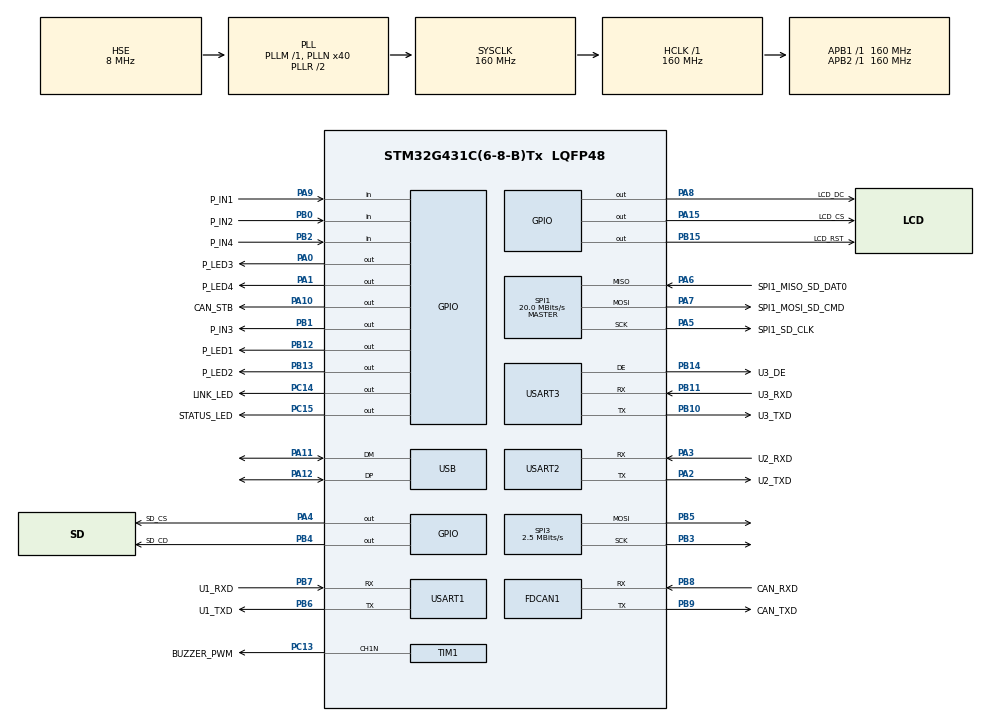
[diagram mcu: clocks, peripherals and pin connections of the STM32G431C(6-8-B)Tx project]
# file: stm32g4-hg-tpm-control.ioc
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Dma.Request0=USART2_RX
Dma.Request1=USART1_RX
Dma.Request2=USART3_RX
Dma.Request3=SPI1_RX
Dma.Request4=SPI1_TX
Dma.SPI1_RX.3.Direction=DMA_PERIPH_TO_MEMORY
Dma.SPI1_RX.3.EventEnable=DISABLE
Dma.SPI1_RX.3.Instance=DMA1_Channel3
Dma.SPI1_RX.3.MemDataAlignment=DMA_MDATAALIGN_BYTE
Dma.SPI1_RX.3.MemInc=DMA_MINC_ENABLE
Dma.SPI1_RX.3.Mode=DMA_CIRCULAR
Dma.SPI1_RX.3.PeriphDataAlignment=DMA_PDATAALIGN_BYTE
Dma.SPI1_RX.3.PeriphInc=DMA_PINC_DISABLE
Dma.SPI1_RX.3.Polarity=HAL_DMAMUX_REQ_GEN_RISING
Dma.SPI1_RX.3.Priority=DMA_PRIORITY_LOW
Dma.SPI1_RX.3.RequestNumber=1
Dma.SPI1_RX.3.SignalID=NONE
Dma.SPI1_RX.3.SyncEnable=DISABLE
Dma.SPI1_RX.3.SyncPolarity=HAL_DMAMUX_SYNC_NO_EVENT
Dma.SPI1_RX.3.SyncRequestNumber=1
Dma.SPI1_RX.3.SyncSignalID=NONE
Dma.SPI1_TX.4.Direction=DMA_MEMORY_TO_PERIPH
Dma.SPI1_TX.4.EventEnable=DISABLE
Dma.SPI1_TX.4.Instance=DMA1_Channel4
Dma.SPI1_TX.4.MemDataAlignment=DMA_MDATAALIGN_BYTE
Dma.SPI1_TX.4.MemInc=DMA_MINC_ENABLE
Dma.SPI1_TX.4.Mode=DMA_CIRCULAR
Dma.SPI1_TX.4.PeriphDataAlignment=DMA_PDATAALIGN_BYTE
Dma.SPI1_TX.4.PeriphInc=DMA_PINC_DISABLE
Dma.SPI1_TX.4.Polarity=HAL_DMAMUX_REQ_GEN_RISING
Dma.SPI1_TX.4.Priority=DMA_PRIORITY_LOW
Dma.SPI1_TX.4.RequestNumber=1
Dma.SPI1_TX.4.SignalID=NONE
Dma.SPI1_TX.4.SyncEnable=DISABLE
Dma.SPI1_TX.4.SyncPolarity=HAL_DMAMUX_SYNC_NO_EVENT
Dma.SPI1_TX.4.SyncRequestNumber=1
Dma.SPI1_TX.4.SyncSignalID=NONE
Dma.USART1_RX.1.Direction=DMA_PERIPH_TO_MEMORY
Dma.USART1_RX.1.EventEnable=DISABLE
Dma.USART1_RX.1.Instance=DMA1_Channel5
Dma.USART1_RX.1.MemDataAlignment=DMA_MDATAALIGN_BYTE
Dma.USART1_RX.1.MemInc=DMA_MINC_ENABLE
Dma.USART1_RX.1.Mode=DMA_CIRCULAR
Dma.USART1_RX.1.PeriphDataAlignment=DMA_PDATAALIGN_BYTE
Dma.USART1_RX.1.PeriphInc=DMA_PINC_DISABLE
Dma.USART1_RX.1.Polarity=HAL_DMAMUX_REQ_GEN_RISING
Dma.USART1_RX.1.Priority=DMA_PRIORITY_LOW
Dma.USART1_RX.1.RequestNumber=1
Dma.USART1_RX.1.SignalID=NONE
Dma.USART1_RX.1.SyncEnable=DISABLE
Dma.USART1_RX.1.SyncPolarity=HAL_DMAMUX_SYNC_NO_EVENT
Dma.USART1_RX.1.SyncRequestNumber=1
Dma.USART1_RX.1.SyncSignalID=NONE
Dma.USART2_RX.0.Direction=DMA_PERIPH_TO_MEMORY
Dma.USART2_RX.0.EventEnable=DISABLE
Dma.USART2_RX.0.Instance=DMA1_Channel1
Dma.USART2_RX.0.MemDataAlignment=DMA_MDATAALIGN_BYTE
Dma.USART2_RX.0.MemInc=DMA_MINC_ENABLE
Dma.USART2_RX.0.Mode=DMA_CIRCULAR
Dma.USART2_RX.0.PeriphDataAlignment=DMA_PDATAALIGN_BYTE
Dma.USART2_RX.0.PeriphInc=DMA_PINC_DISABLE
Dma.USART2_RX.0.Polarity=HAL_DMAMUX_REQ_GEN_RISING
Dma.USART2_RX.0.Priority=DMA_PRIORITY_LOW
Dma.USART2_RX.0.RequestNumber=1
Dma.USART2_RX.0.SignalID=NONE
Dma.USART2_RX.0.SyncEnable=DISABLE
Dma.USART2_RX.0.SyncPolarity=HAL_DMAMUX_SYNC_NO_EVENT
Dma.USART2_RX.0.SyncRequestNumber=1
Dma.USART2_RX.0.SyncSignalID=NONE
Dma.USART3_RX.2.Direction=DMA_PERIPH_TO_MEMORY
Dma.USART3_RX.2.EventEnable=DISABLE
Dma.USART3_RX.2.Instance=DMA1_Channel2
Dma.USART3_RX.2.MemDataAlignment=DMA_MDATAALIGN_BYTE
Dma.USART3_RX.2.MemInc=DMA_MINC_ENABLE
Dma.USART3_RX.2.Mode=DMA_CIRCULAR
Dma.USART3_RX.2.PeriphDataAlignment=DMA_PDATAALIGN_BYTE
Dma.USART3_RX.2.PeriphInc=DMA_PINC_DISABLE
Dma.USART3_RX.2.Polarity=HAL_DMAMUX_REQ_GEN_RISING
Dma.USART3_RX.2.Priority=DMA_PRIORITY_LOW
Dma.USART3_RX.2.RequestNumber=1
Dma.USART3_RX.2.SignalID=NONE
Dma.USART3_RX.2.SyncEnable=DISABLE
Dma.USART3_RX.2.SyncPolarity=HAL_DMAMUX_SYNC_NO_EVENT
Dma.USART3_RX.2.SyncRequestNumber=1
Dma.USART3_RX.2.SyncSignalID=NONE
FDCAN1.CalculateBaudRateNominal=1000000
FDCAN1.CalculateTimeBitNominal=1000
FDCAN1.CalculateTimeQuantumNominal=200.0
FDCAN1.ExtFiltersNbr=8
FDCAN1.StdFiltersNbr=28
Mcu.Family=STM32G4
Mcu.Name=STM32G431C(6-8-B)Tx
Mcu.Package=LQFP48
NVIC.FDCAN1_IT0_IRQn=true\:0\:0\:false\:false\:true\:true\:true\:true
NVIC.PriorityGroup=NVIC_PRIORITYGROUP_4
NVIC.USB_LP_IRQn=true\:0\:0\:false\:false\:true\:false\:true\:true
PA0.GPIO_Label=P_LED3
PA0.Signal=GPIO_Output
PA1.GPIO_Label=P_LED4
PA1.Signal=GPIO_Output
PA10.GPIO_Label=CAN_STB
PA10.PinState=GPIO_PIN_RESET
PA10.Signal=GPIO_Output
PA11.Mode=Device
PA11.Signal=USB_DM
PA12.Mode=Device
PA12.Signal=USB_DP
PA13.Mode=Serial_Wire
PA13.Signal=SYS_JTMS-SWDIO
PA14.Mode=Serial_Wire
PA14.Signal=SYS_JTCK-SWCLK
PA15.GPIO_Label=LCD_CS
PA15.Signal=GPIO_Output
PA2.GPIO_Label=U2_TXD
PA2.Mode=Asynchronous
PA2.Signal=USART2_TX
PA3.GPIO_Label=U2_RXD
PA3.Mode=Asynchronous
PA3.Signal=USART2_RX
PA4.GPIO_Label=SD_CS
PA4.Signal=GPIO_Output
PA5.GPIO_Label=SPI1_SD_CLK
PA5.GPIO_Speed=GPIO_SPEED_FREQ_VERY_HIGH
PA5.Mode=Full_Duplex_Master
PA5.Signal=SPI1_SCK
PA6.GPIO_Label=SPI1_MISO_SD_DAT0
PA6.GPIO_Speed=GPIO_SPEED_FREQ_VERY_HIGH
PA6.Mode=Full_Duplex_Master
PA6.Signal=SPI1_MISO
PA7.GPIO_Label=SPI1_MOSI_SD_CMD
PA7.GPIO_Speed=GPIO_SPEED_FREQ_VERY_HIGH
PA7.Mode=Full_Duplex_Master
PA7.Signal=SPI1_MOSI
PA8.GPIO_Label=LCD_DC
PA8.Signal=GPIO_Output
PA9.GPIO_Label=P_IN1
PA9.Signal=GPIO_Input
PB0.GPIO_Label=P_IN2
PB0.Signal=GPIO_Input
PB1.GPIO_Label=P_IN3
PB1.Signal=GPIO_Output
PB10.GPIO_Label=U3_TXD
PB10.Mode=Asynchronous
PB10.Signal=USART3_TX
PB11.GPIO_Label=U3_RXD
PB11.Mode=Asynchronous
PB11.Signal=USART3_RX
PB12.GPIO_Label=P_LED1
PB12.Signal=GPIO_Output
PB13.GPIO_Label=P_LED2
PB13.Signal=GPIO_Output
PB14.GPIO_Label=U3_DE
PB14.Mode=Hardware Flow Control (RS485)
PB14.Signal=USART3_DE
PB15.GPIO_Label=LCD_RST
PB15.Signal=GPIO_Output
PB2.GPIO_Label=P_IN4
PB2.Signal=GPIO_Input
PB3.GPIO_Speed=GPIO_SPEED_FREQ_VERY_HIGH
PB3.Mode=TX_Only_Simplex_Unidirect_Master
PB3.Signal=SPI3_SCK
PB4.GPIO_Label=SD_CD
PB4.Signal=GPIO_Output
PB5.GPIO_Speed=GPIO_SPEED_FREQ_VERY_HIGH
PB5.Mode=TX_Only_Simplex_Unidirect_Master
PB5.Signal=SPI3_MOSI
PB6.GPIO_Label=U1_TXD
PB6.Mode=Asynchronous
PB6.Signal=USART1_TX
PB7.GPIO_Label=U1_RXD
PB7.Mode=Asynchronous
PB7.Signal=USART1_RX
PB8-BOOT0.GPIO_Label=CAN_RXD
PB8-BOOT0.Mode=FDCAN_Activate
PB8-BOOT0.Signal=FDCAN1_RX
PB9.GPIO_Label=CAN_TXD
PB9.Mode=FDCAN_Activate
PB9.Signal=FDCAN1_TX
PC13.GPIO_Label=BUZZER_PWM
PC13.Mode=PWM Generation1 CH1N
PC13.Signal=TIM1_CH1N
PC14-OSC32_IN.GPIO_Label=LINK_LED
PC14-OSC32_IN.Signal=GPIO_Output
PC15-OSC32_OUT.GPIO_Label=STATUS_LED
PC15-OSC32_OUT.Signal=GPIO_Output
PF0-OSC_IN.Mode=HSE-External-Oscillator
PF0-OSC_IN.Signal=RCC_OSC_IN
PF1-OSC_OUT.Mode=HSE-External-Oscillator
PF1-OSC_OUT.Signal=RCC_OSC_OUT
ProjectManager.HeapSize=0x200
ProjectManager.StackSize=0x400
ProjectManager.TargetToolchain=STM32CubeIDE
RCC.ADC12Freq_Value=160000000
RCC.AHBFreq_Value=160000000
RCC.APB1Freq_Value=160000000
RCC.APB1TimFreq_Value=160000000
RCC.APB2Freq_Value=160000000
RCC.APB2TimFreq_Value=160000000
RCC.CK48CLockSelection=RCC_USBCLKSOURCE_HSI48
RCC.CortexFreq_Value=160000000
RCC.EXTERNAL_CLOCK_VALUE=12288000
RCC.FDCANCLockSelection=RCC_FDCANCLKSOURCE_PLL
RCC.HCLKFreq_Value=160000000
RCC.HSE_VALUE=8000000
RCC.HSI48_VALUE=48000000
RCC.HSI_VALUE=16000000
RCC.LSE_VALUE=32768
RCC.PLLN=40
RCC.PLLQ=RCC_PLLQ_DIV4
RCC.PLLSourceVirtual=RCC_PLLSOURCE_HSE
RCC.SYSCLKFreq_VALUE=160000000
RCC.SYSCLKSource=RCC_SYSCLKSOURCE_PLLCLK
RCC.USBFreq_Value=48000000
RCC.VCOOutputFreq_Value=320000000
SPI1.BaudRatePrescaler=SPI_BAUDRATEPRESCALER_8
SPI1.CalculateBaudRate=20.0 MBits/s
SPI1.DataSize=SPI_DATASIZE_8BIT
SPI1.Direction=SPI_DIRECTION_2LINES
SPI1.Mode=SPI_MODE_MASTER
SPI1.VirtualType=VM_MASTER
SPI3.BaudRatePrescaler=SPI_BAUDRATEPRESCALER_64
SPI3.CalculateBaudRate=2.5 MBits/s
SPI3.DataSize=SPI_DATASIZE_8BIT
SPI3.Direction=SPI_DIRECTION_2LINES
SPI3.Mode=SPI_MODE_MASTER
SPI3.VirtualType=VM_MASTER
TIM1.Channel-PWM\ Generation1\ CH1N=TIM_CHANNEL_1
USART1.SwapParam=ADVFEATURE_SWAP_ENABLE
USART1.VirtualMode-Asynchronous=VM_ASYNC
USART2.VirtualMode-Asynchronous=VM_ASYNC
USART3.VirtualMode-Asynchronous=VM_ASYNC
USART3.VirtualMode-Hardware\ Flow\ Control\ (RS485)=VM_ASYNC
USB.Sof_enable=ENABLE
USB_DEVICE.CLASS_NAME_FS=CDC
USB_DEVICE.USBD_MAX_STR_DESC_SIZ=1024
USB_DEVICE.VirtualMode=Cdc
USB_DEVICE.VirtualModeFS=Cdc_FS
VP_SYS_VS_DBSignals.Mode=DisableDeadBatterySignals
VP_USB_DEVICE_VS_USB_DEVICE_CDC_FS.Mode=CDC_FS
board=custom

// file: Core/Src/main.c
/* USER CODE BEGIN Header */
/**
  ******************************************************************************
  * @file           : main.c
  * @brief          : Main program body
  ******************************************************************************
  * @attention
  *
  * Copyright (c) 2024 STMicroelectronics.
  * All rights reserved.
  *
  * This software is licensed under terms that can be found in the LICENSE file
  * in the root directory of this software component.
  * If no LICENSE file comes with this software, it is provided AS-IS.
  *
  ******************************************************************************
  */
/* USER CODE END Header */
#include "main.h"
#include "dma.h"
#include "fdcan.h"
#include "spi.h"
#include "tim.h"
#include "usart.h"
#include "usb_device.h"
#include "gpio.h"

/* USER CODE BEGIN Includes */
#include "ap.h"
/* USER CODE END Includes */

void SystemClock_Config(void);
/* USER CODE BEGIN PFP */
void mxInit();
/* USER CODE END PFP */

int main(void)
{

  /* MCU Configuration--------------------------------------------------------*/

  /* Reset of all peripherals, Initializes the Flash interface and the Systick. */
  HAL_Init();

  /* Configure the system clock */
  SystemClock_Config();

  /* Initialize all configured peripherals */
  MX_GPIO_Init();
  MX_DMA_Init();
  MX_FDCAN1_Init();
  MX_USART1_UART_Init();
  MX_USART2_UART_Init();
  MX_USB_Device_Init();
  MX_SPI3_Init();
  MX_SPI1_Init();
  MX_TIM1_Init();
  MX_USART3_UART_Init();
  /* USER CODE BEGIN 2 */
  hwInit();
  apInit();
  apMain();
  /* USER CODE END 2 */

  /* Infinite loop */
  while (1)
  {

  }
}

void SystemClock_Config(void)
{
  RCC_OscInitTypeDef RCC_OscInitStruct = {0};
  RCC_ClkInitTypeDef RCC_ClkInitStruct = {0};

  /** Configure the main internal regulator output voltage
  */
  HAL_PWREx_ControlVoltageScaling(PWR_REGULATOR_VOLTAGE_SCALE1_BOOST);

  /** Initializes the RCC Oscillators according to the specified parameters
  * in the RCC_OscInitTypeDef structure.
  */
  RCC_OscInitStruct.OscillatorType = RCC_OSCILLATORTYPE_HSI48|RCC_OSCILLATORTYPE_HSE;
  RCC_OscInitStruct.HSEState = RCC_HSE_ON;
  RCC_OscInitStruct.HSI48State = RCC_HSI48_ON;
  RCC_OscInitStruct.PLL.PLLState = RCC_PLL_ON;
  RCC_OscInitStruct.PLL.PLLSource = RCC_PLLSOURCE_HSE;
  RCC_OscInitStruct.PLL.PLLM = RCC_PLLM_DIV1;
  RCC_OscInitStruct.PLL.PLLN = 40;
  RCC_OscInitStruct.PLL.PLLP = RCC_PLLP_DIV2;
  RCC_OscInitStruct.PLL.PLLQ = RCC_PLLQ_DIV4;
  RCC_OscInitStruct.PLL.PLLR = RCC_PLLR_DIV2;
  if (HAL_RCC_OscConfig(&RCC_OscInitStruct) != HAL_OK)
  {
    Error_Handler();
  }

  /** Initializes the CPU, AHB and APB buses clocks
  */
  RCC_ClkInitStruct.ClockType = RCC_CLOCKTYPE_HCLK|RCC_CLOCKTYPE_SYSCLK
                              |RCC_CLOCKTYPE_PCLK1|RCC_CLOCKTYPE_PCLK2;
  RCC_ClkInitStruct.SYSCLKSource = RCC_SYSCLKSOURCE_PLLCLK;
  RCC_ClkInitStruct.AHBCLKDivider = RCC_SYSCLK_DIV1;
  RCC_ClkInitStruct.APB1CLKDivider = RCC_HCLK_DIV1;
  RCC_ClkInitStruct.APB2CLKDivider = RCC_HCLK_DIV1;

  if (HAL_RCC_ClockConfig(&RCC_ClkInitStruct, FLASH_LATENCY_4) != HAL_OK)
  {
    Error_Handler();
  }
}

void Error_Handler(void)
{
  __disable_irq();
  while (1)
  {
  }
}
